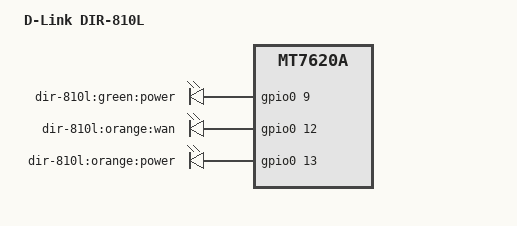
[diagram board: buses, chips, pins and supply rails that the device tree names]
/dts-v1/;

#include "mt7620a_cameo_810.dtsi"

/ {
	compatible = "dlink,dir-810l", "ralink,mt7620a-soc";
	model = "D-Link DIR-810L";

	aliases {
		led-boot = &led_power_green;
		led-failsafe = &led_power_green;
		led-running = &led_power_green;
		led-upgrade = &led_power_green;
		label-mac-device = &ethernet;
	};

	leds {
		compatible = "gpio-leds";

		led_power_green: power_green {
			label = "dir-810l:green:power";
			gpios = <&gpio0 9 GPIO_ACTIVE_HIGH>;
		};

		wan {
			label = "dir-810l:orange:wan";
			gpios = <&gpio0 12 GPIO_ACTIVE_HIGH>;
		};

		power_orange {
			label = "dir-810l:orange:power";
			gpios = <&gpio0 13 GPIO_ACTIVE_HIGH>;
		};
	};
};

&state_default {
	gpio {
		groups = "i2c", "uartf";
		function = "gpio";
	};
};

&gsw {
	pinctrl-names = "default";
	pinctrl-0 = <&ephy_pins>;

	mediatek,port4 = "ephy";
};
